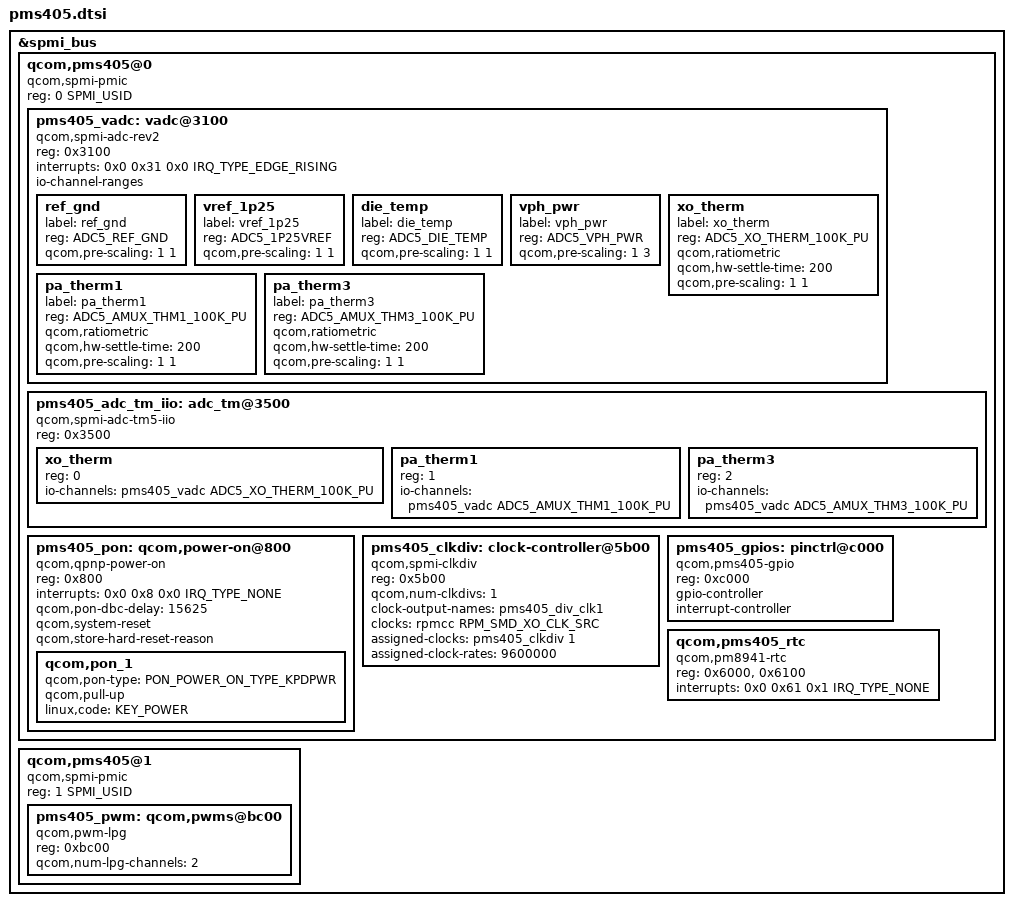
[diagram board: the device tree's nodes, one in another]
#include <dt-bindings/input/linux-event-codes.h>
#include <dt-bindings/input/qcom,qpnp-power-on.h>
#include <dt-bindings/iio/qcom,spmi-vadc.h>
#include <dt-bindings/spmi/spmi.h>

&spmi_bus {
	qcom,pms405@0 {
		compatible ="qcom,spmi-pmic";
		reg = <0 SPMI_USID>;
		#address-cells = <1>;
		#size-cells = <0>;

		pms405_vadc: vadc@3100 {
			compatible = "qcom,spmi-adc-rev2";
			reg = <0x3100>;
			#address-cells = <1>;
			#size-cells = <0>;
			interrupts = <0x0 0x31 0x0 IRQ_TYPE_EDGE_RISING>;
			#io-channel-cells = <1>;
			io-channel-ranges;

			ref_gnd {
				label = "ref_gnd";
				reg = <ADC5_REF_GND>;
				qcom,pre-scaling = <1 1>;
			};

			vref_1p25 {
				label = "vref_1p25";
				reg = <ADC5_1P25VREF>;
				qcom,pre-scaling = <1 1>;
			};

			die_temp {
				label = "die_temp";
				reg = <ADC5_DIE_TEMP>;
				qcom,pre-scaling = <1 1>;
			};

			vph_pwr {
				label = "vph_pwr";
				reg = <ADC5_VPH_PWR>;
				qcom,pre-scaling = <1 3>;
			};

			xo_therm {
				label = "xo_therm";
				reg = <ADC5_XO_THERM_100K_PU>;
				qcom,ratiometric;
				qcom,hw-settle-time = <200>;
				qcom,pre-scaling = <1 1>;
			};

			pa_therm1 {
				label = "pa_therm1";
				reg = <ADC5_AMUX_THM1_100K_PU>;
				qcom,ratiometric;
				qcom,hw-settle-time = <200>;
				qcom,pre-scaling = <1 1>;
			};

			pa_therm3 {
				label = "pa_therm3";
				reg = <ADC5_AMUX_THM3_100K_PU>;
				qcom,ratiometric;
				qcom,hw-settle-time = <200>;
				qcom,pre-scaling = <1 1>;
			};
		};

		pms405_adc_tm_iio: adc_tm@3500 {
			compatible = "qcom,spmi-adc-tm5-iio";
			reg = <0x3500>;
			#thermal-sensor-cells = <1>;
			#address-cells = <1>;
			#size-cells = <0>;

			xo_therm {
				reg = <0>;
				io-channels = <&pms405_vadc ADC5_XO_THERM_100K_PU>;
			};

			pa_therm1 {
				reg = <1>;
				io-channels = <&pms405_vadc ADC5_AMUX_THM1_100K_PU>;
			};

			pa_therm3 {
				reg = <2>;
				io-channels = <&pms405_vadc ADC5_AMUX_THM3_100K_PU>;
			};
		};

		pms405_pon: qcom,power-on@800 {
			compatible = "qcom,qpnp-power-on";
			reg = <0x800>;
			interrupts = <0x0 0x8 0x0 IRQ_TYPE_NONE>;
			interrupt-names = "kpdpwr";
			qcom,pon-dbc-delay = <15625>;
			qcom,system-reset;
			qcom,store-hard-reset-reason;

			qcom,pon_1 {
				qcom,pon-type = <PON_POWER_ON_TYPE_KPDPWR>;
				qcom,pull-up;
				linux,code = <KEY_POWER>;
			};
		};

		pms405_clkdiv: clock-controller@5b00 {
			compatible = "qcom,spmi-clkdiv";
			reg = <0x5b00>;
			#clock-cells = <1>;
			qcom,num-clkdivs = <1>;
			clock-output-names = "pms405_div_clk1";
			clocks = <&rpmcc RPM_SMD_XO_CLK_SRC>;
			clock-names = "xo";
			assigned-clocks = <&pms405_clkdiv 1>;
			assigned-clock-rates = <9600000>;
		};

		/* QCS405 + PMS405 GPIO configuration */
		pms405_gpios: pinctrl@c000 {
			compatible = "qcom,pms405-gpio";
			reg = <0xc000>;
			gpio-controller;
			#gpio-cells = <2>;
			interrupt-controller;
			#interrupt-cells = <2>;
		};

		qcom,pms405_rtc {
			compatible = "qcom,pm8941-rtc";
			reg = <0x6000>, <0x6100>;
			reg-names = "rtc", "alarm";
			interrupts = <0x0 0x61 0x1 IRQ_TYPE_NONE>;
		};
	};

	qcom,pms405@1 {
		compatible = "qcom,spmi-pmic";
		reg = <1 SPMI_USID>;
		#address-cells = <1>;
		#size-cells = <0>;

		pms405_pwm: qcom,pwms@bc00 {
			compatible = "qcom,pwm-lpg";
			reg = <0xbc00>;
			reg-names = "lpg-base";
			qcom,num-lpg-channels = <2>;
			#pwm-cells = <2>;
		};
	};
};
